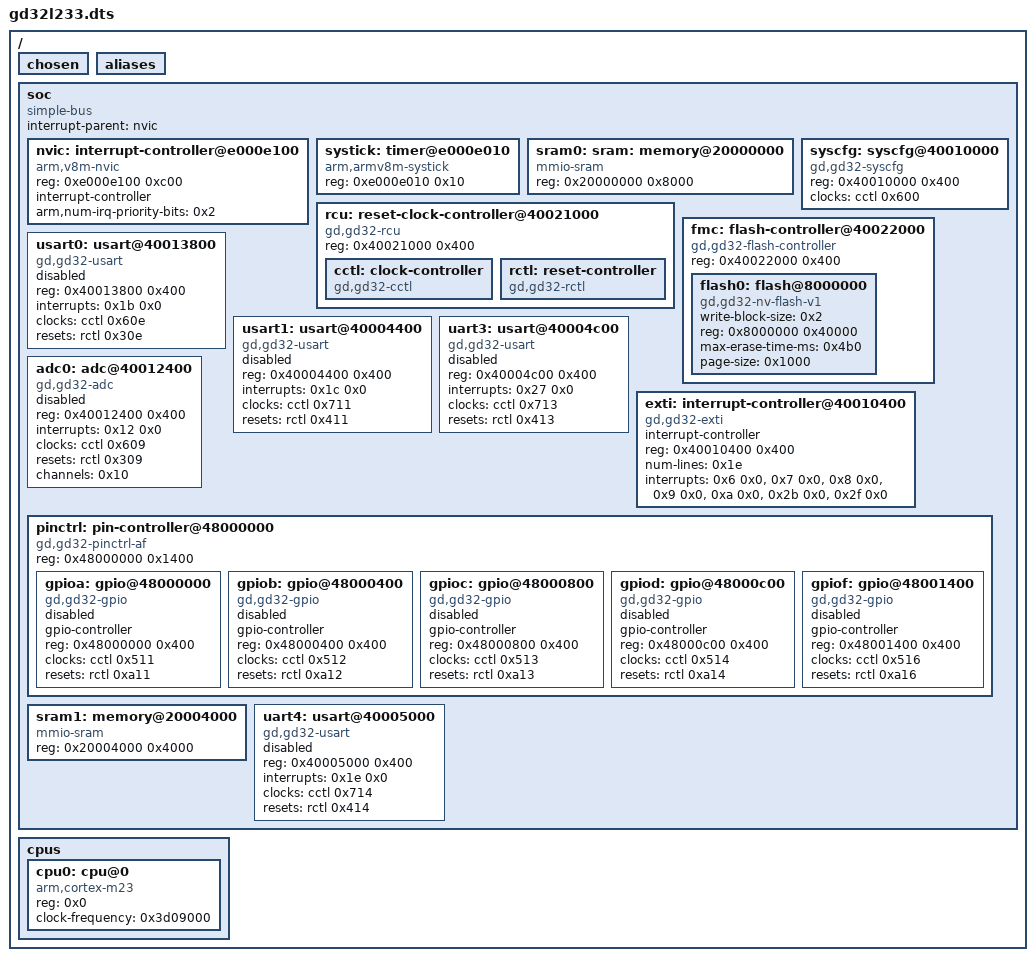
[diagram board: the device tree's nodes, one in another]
/dts-v1/;

/ {
	#address-cells = < 0x1 >;
	#size-cells = < 0x1 >;
	chosen {
	};
	aliases {
	};
	soc {
		#address-cells = < 0x1 >;
		#size-cells = < 0x1 >;
		compatible = "simple-bus";
		interrupt-parent = < &nvic >;
		ranges;
		nvic: interrupt-controller@e000e100 {
			#address-cells = < 0x1 >;
			compatible = "arm,v8m-nvic";
			reg = < 0xe000e100 0xc00 >;
			interrupt-controller;
			#interrupt-cells = < 0x2 >;
			arm,num-irq-priority-bits = < 0x2 >;
			phandle = < 0x1 >;
		};
		systick: timer@e000e010 {
			compatible = "arm,armv8m-systick";
			reg = < 0xe000e010 0x10 >;
		};
		sram0: sram: memory@20000000 {
			compatible = "mmio-sram";
			reg = < 0x20000000 0x8000 >;
		};
		rcu: reset-clock-controller@40021000 {
			compatible = "gd,gd32-rcu";
			reg = < 0x40021000 0x400 >;
			status = "okay";
			cctl: clock-controller {
				compatible = "gd,gd32-cctl";
				#clock-cells = < 0x1 >;
				status = "okay";
				phandle = < 0x2 >;
			};
			rctl: reset-controller {
				compatible = "gd,gd32-rctl";
				#reset-cells = < 0x1 >;
				status = "okay";
				phandle = < 0x3 >;
			};
		};
		syscfg: syscfg@40010000 {
			compatible = "gd,gd32-syscfg";
			reg = < 0x40010000 0x400 >;
			clocks = < &cctl 0x600 >;
		};
		fmc: flash-controller@40022000 {
			compatible = "gd,gd32-flash-controller";
			reg = < 0x40022000 0x400 >;
			#address-cells = < 0x1 >;
			#size-cells = < 0x1 >;
			flash0: flash@8000000 {
				compatible = "gd,gd32-nv-flash-v1", "soc-nv-flash";
				write-block-size = < 0x2 >;
				reg = < 0x8000000 0x40000 >;
				max-erase-time-ms = < 0x4b0 >;
				page-size = < 0x1000 >;
			};
		};
		usart0: usart@40013800 {
			compatible = "gd,gd32-usart";
			reg = < 0x40013800 0x400 >;
			interrupts = < 0x1b 0x0 >;
			clocks = < &cctl 0x60e >;
			resets = < &rctl 0x30e >;
			status = "disabled";
		};
		usart1: usart@40004400 {
			compatible = "gd,gd32-usart";
			reg = < 0x40004400 0x400 >;
			interrupts = < 0x1c 0x0 >;
			clocks = < &cctl 0x711 >;
			resets = < &rctl 0x411 >;
			status = "disabled";
		};
		uart3: usart@40004c00 {
			compatible = "gd,gd32-usart";
			reg = < 0x40004c00 0x400 >;
			interrupts = < 0x27 0x0 >;
			clocks = < &cctl 0x713 >;
			resets = < &rctl 0x413 >;
			status = "disabled";
		};
		adc0: adc@40012400 {
			compatible = "gd,gd32-adc";
			reg = < 0x40012400 0x400 >;
			interrupts = < 0x12 0x0 >;
			clocks = < &cctl 0x609 >;
			resets = < &rctl 0x309 >;
			channels = < 0x10 >;
			status = "disabled";
			#io-channel-cells = < 0x1 >;
		};
		exti: interrupt-controller@40010400 {
			compatible = "gd,gd32-exti";
			interrupt-controller;
			#interrupt-cells = < 0x1 >;
			reg = < 0x40010400 0x400 >;
			num-lines = < 0x1e >;
			interrupts = < 0x6 0x0 >, < 0x7 0x0 >, < 0x8 0x0 >, < 0x9 0x0 >, < 0xa 0x0 >, < 0x2b 0x0 >, < 0x2f 0x0 >;
			interrupt-names = "line0", "line1", "line2", "line3", "line4", "line5-9", "line10-15";
			status = "okay";
		};
		pinctrl: pin-controller@48000000 {
			compatible = "gd,gd32-pinctrl-af";
			reg = < 0x48000000 0x1400 >;
			#address-cells = < 0x1 >;
			#size-cells = < 0x1 >;
			status = "okay";
			gpioa: gpio@48000000 {
				compatible = "gd,gd32-gpio";
				gpio-controller;
				#gpio-cells = < 0x2 >;
				reg = < 0x48000000 0x400 >;
				clocks = < &cctl 0x511 >;
				resets = < &rctl 0xa11 >;
				status = "disabled";
			};
			gpiob: gpio@48000400 {
				compatible = "gd,gd32-gpio";
				gpio-controller;
				#gpio-cells = < 0x2 >;
				reg = < 0x48000400 0x400 >;
				clocks = < &cctl 0x512 >;
				resets = < &rctl 0xa12 >;
				status = "disabled";
			};
			gpioc: gpio@48000800 {
				compatible = "gd,gd32-gpio";
				gpio-controller;
				#gpio-cells = < 0x2 >;
				reg = < 0x48000800 0x400 >;
				clocks = < &cctl 0x513 >;
				resets = < &rctl 0xa13 >;
				status = "disabled";
			};
			gpiod: gpio@48000c00 {
				compatible = "gd,gd32-gpio";
				gpio-controller;
				#gpio-cells = < 0x2 >;
				reg = < 0x48000c00 0x400 >;
				clocks = < &cctl 0x514 >;
				resets = < &rctl 0xa14 >;
				status = "disabled";
			};
			gpiof: gpio@48001400 {
				compatible = "gd,gd32-gpio";
				gpio-controller;
				#gpio-cells = < 0x2 >;
				reg = < 0x48001400 0x400 >;
				clocks = < &cctl 0x516 >;
				resets = < &rctl 0xa16 >;
				status = "disabled";
			};
		};
		sram1: memory@20004000 {
			compatible = "mmio-sram";
			reg = < 0x20004000 0x4000 >;
		};
		uart4: usart@40005000 {
			compatible = "gd,gd32-usart";
			reg = < 0x40005000 0x400 >;
			interrupts = < 0x1e 0x0 >;
			clocks = < &cctl 0x714 >;
			resets = < &rctl 0x414 >;
			status = "disabled";
		};
	};
	cpus {
		#address-cells = < 0x1 >;
		#size-cells = < 0x0 >;
		cpu0: cpu@0 {
			compatible = "arm,cortex-m23";
			reg = < 0x0 >;
			clock-frequency = < 0x3d09000 >;
		};
	};
};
